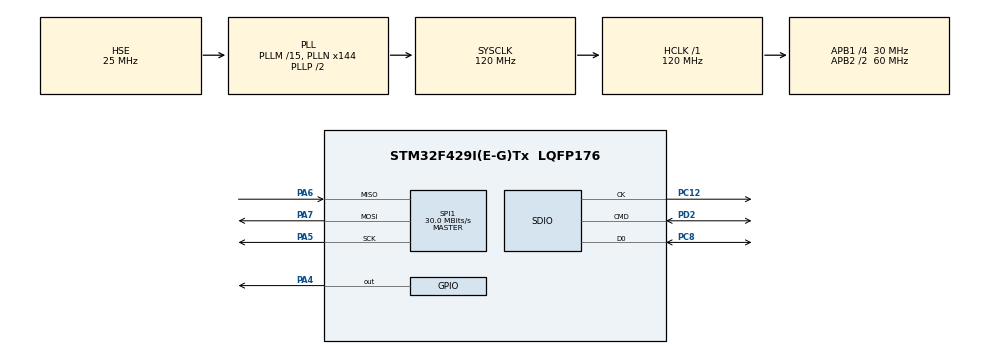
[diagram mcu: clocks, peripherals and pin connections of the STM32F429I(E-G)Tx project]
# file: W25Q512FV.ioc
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Dma.Request0=SDIO_RX
Dma.Request1=SDIO_TX
Dma.SDIO_RX.0.Direction=DMA_PERIPH_TO_MEMORY
Dma.SDIO_RX.0.FIFOMode=DMA_FIFOMODE_ENABLE
Dma.SDIO_RX.0.FIFOThreshold=DMA_FIFO_THRESHOLD_FULL
Dma.SDIO_RX.0.Instance=DMA2_Stream3
Dma.SDIO_RX.0.MemBurst=DMA_MBURST_INC4
Dma.SDIO_RX.0.MemDataAlignment=DMA_MDATAALIGN_WORD
Dma.SDIO_RX.0.MemInc=DMA_MINC_ENABLE
Dma.SDIO_RX.0.Mode=DMA_PFCTRL
Dma.SDIO_RX.0.PeriphBurst=DMA_PBURST_INC4
Dma.SDIO_RX.0.PeriphDataAlignment=DMA_PDATAALIGN_WORD
Dma.SDIO_RX.0.PeriphInc=DMA_PINC_DISABLE
Dma.SDIO_RX.0.Priority=DMA_PRIORITY_MEDIUM
Dma.SDIO_TX.1.Direction=DMA_MEMORY_TO_PERIPH
Dma.SDIO_TX.1.FIFOMode=DMA_FIFOMODE_ENABLE
Dma.SDIO_TX.1.FIFOThreshold=DMA_FIFO_THRESHOLD_FULL
Dma.SDIO_TX.1.Instance=DMA2_Stream6
Dma.SDIO_TX.1.MemBurst=DMA_MBURST_INC4
Dma.SDIO_TX.1.MemDataAlignment=DMA_MDATAALIGN_WORD
Dma.SDIO_TX.1.MemInc=DMA_MINC_ENABLE
Dma.SDIO_TX.1.Mode=DMA_PFCTRL
Dma.SDIO_TX.1.PeriphBurst=DMA_PBURST_INC4
Dma.SDIO_TX.1.PeriphDataAlignment=DMA_PDATAALIGN_WORD
Dma.SDIO_TX.1.PeriphInc=DMA_PINC_DISABLE
Dma.SDIO_TX.1.Priority=DMA_PRIORITY_LOW
Mcu.Family=STM32F4
Mcu.Name=STM32F429I(E-G)Tx
Mcu.Package=LQFP176
NVIC.DMA2_Stream3_IRQn=true\:0\:0\:false\:false\:true\:false\:true\:true
NVIC.DMA2_Stream6_IRQn=true\:0\:0\:false\:false\:true\:false\:true\:true
NVIC.PriorityGroup=NVIC_PRIORITYGROUP_4
NVIC.SDIO_IRQn=true\:0\:0\:false\:false\:true\:true\:true\:true
NVIC.TIM4_IRQn=true\:0\:0\:true\:false\:true\:false\:true\:true
NVIC.TimeBase=TIM4_IRQn
NVIC.TimeBaseIP=TIM4
PA13.Mode=Serial_Wire
PA13.Signal=SYS_JTMS-SWDIO
PA14.Mode=Serial_Wire
PA14.Signal=SYS_JTCK-SWCLK
PA4.GPIO_Speed=GPIO_SPEED_FREQ_HIGH
PA4.PinState=GPIO_PIN_SET
PA4.Signal=GPIO_Output
PA5.Mode=Full_Duplex_Master
PA5.Signal=SPI1_SCK
PA6.Mode=Full_Duplex_Master
PA6.Signal=SPI1_MISO
PA7.Mode=Full_Duplex_Master
PA7.Signal=SPI1_MOSI
PC12.Mode=SD_1_bit
PC12.Signal=SDIO_CK
PC14/OSC32_IN.Mode=LSE-External-Oscillator
PC14/OSC32_IN.Signal=RCC_OSC32_IN
PC15/OSC32_OUT.Mode=LSE-External-Oscillator
PC15/OSC32_OUT.Signal=RCC_OSC32_OUT
PC8.Mode=SD_1_bit
PC8.Signal=SDIO_D0
PD2.Mode=SD_1_bit
PD2.Signal=SDIO_CMD
PH0/OSC_IN.Mode=HSE-External-Oscillator
PH0/OSC_IN.Signal=RCC_OSC_IN
PH1/OSC_OUT.Mode=HSE-External-Oscillator
PH1/OSC_OUT.Signal=RCC_OSC_OUT
ProjectManager.HeapSize=0x200
ProjectManager.StackSize=0x400
ProjectManager.TargetToolchain=STM32CubeIDE
RCC.48MHZClocksFreq_Value=48000000
RCC.AHBFreq_Value=120000000
RCC.APB1CLKDivider=RCC_HCLK_DIV4
RCC.APB1Freq_Value=30000000
RCC.APB1TimFreq_Value=60000000
RCC.APB2CLKDivider=RCC_HCLK_DIV2
RCC.APB2Freq_Value=60000000
RCC.APB2TimFreq_Value=120000000
RCC.CortexFreq_Value=120000000
RCC.HCLKFreq_Value=120000000
RCC.HSE_VALUE=25000000
RCC.HSI_VALUE=16000000
RCC.PLLM=15
RCC.PLLN=144
RCC.PLLQ=5
RCC.PLLSourceVirtual=RCC_PLLSOURCE_HSE
RCC.SYSCLKFreq_VALUE=120000000
RCC.SYSCLKSource=RCC_SYSCLKSOURCE_PLLCLK
RCC.VCOOutputFreq_Value=240000000
SPI1.BaudRatePrescaler=SPI_BAUDRATEPRESCALER_2
SPI1.CalculateBaudRate=30.0 MBits/s
SPI1.Direction=SPI_DIRECTION_2LINES
SPI1.Mode=SPI_MODE_MASTER
SPI1.VirtualType=VM_MASTER
VP_SYS_VS_tim4.Mode=TIM4
board=custom

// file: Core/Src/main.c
/* USER CODE BEGIN Header */
/**
  ******************************************************************************
  * @file           : main.c
  * @brief          : Main program body
  ******************************************************************************
  * @attention
  *
  * Copyright (c) 2025 STMicroelectronics.
  * All rights reserved.
  *
  * This software is licensed under terms that can be found in the LICENSE file
  * in the root directory of this software component.
  * If no LICENSE file comes with this software, it is provided AS-IS.
  *
  ******************************************************************************
  */
/* USER CODE END Header */
#include "main.h"
#include "dma.h"
#include "sdio.h"
#include "spi.h"
#include "gpio.h"

/* USER CODE BEGIN Includes */
#include "w25q512.h"
#include "SD.h"
#include "Test1.h"
#include "SDToFlash.h"
/* USER CODE END Includes */

void SystemClock_Config(void);

int main(void)
{

  /* MCU Configuration--------------------------------------------------------*/

  /* Reset of all peripherals, Initializes the Flash interface and the Systick. */
  HAL_Init();

  /* Configure the system clock */
  SystemClock_Config();

  /* USER CODE BEGIN SysInit */
  app_log("right f429");
  /* USER CODE END SysInit */

  /* Initialize all configured peripherals */
  MX_GPIO_Init();
  MX_DMA_Init();
  MX_SPI1_Init();
  MX_SDIO_SD_Init();
  /* USER CODE BEGIN 2 */
  W25Q512Init();
  app_log("right f429");

//  SDToFlashTest();
  TraversalDirectory("1:");
//  TraversalDirectory("0:");
//  ReadFileCatalogue();

  /* USER CODE END 2 */

  /* Infinite loop */
  while (1)
  {

  }
}

void SystemClock_Config(void)
{
  RCC_OscInitTypeDef RCC_OscInitStruct = {0};
  RCC_ClkInitTypeDef RCC_ClkInitStruct = {0};

  /** Configure the main internal regulator output voltage
  */
  __HAL_RCC_PWR_CLK_ENABLE();
  __HAL_PWR_VOLTAGESCALING_CONFIG(PWR_REGULATOR_VOLTAGE_SCALE3);

  /** Initializes the RCC Oscillators according to the specified parameters
  * in the RCC_OscInitTypeDef structure.
  */
  RCC_OscInitStruct.OscillatorType = RCC_OSCILLATORTYPE_HSE;
  RCC_OscInitStruct.HSEState = RCC_HSE_ON;
  RCC_OscInitStruct.PLL.PLLState = RCC_PLL_ON;
  RCC_OscInitStruct.PLL.PLLSource = RCC_PLLSOURCE_HSE;
  RCC_OscInitStruct.PLL.PLLM = 15;
  RCC_OscInitStruct.PLL.PLLN = 144;
  RCC_OscInitStruct.PLL.PLLP = RCC_PLLP_DIV2;
  RCC_OscInitStruct.PLL.PLLQ = 5;
  if (HAL_RCC_OscConfig(&RCC_OscInitStruct) != HAL_OK)
  {
    Error_Handler();
  }

  /** Initializes the CPU, AHB and APB buses clocks
  */
  RCC_ClkInitStruct.ClockType = RCC_CLOCKTYPE_HCLK|RCC_CLOCKTYPE_SYSCLK
                              |RCC_CLOCKTYPE_PCLK1|RCC_CLOCKTYPE_PCLK2;
  RCC_ClkInitStruct.SYSCLKSource = RCC_SYSCLKSOURCE_PLLCLK;
  RCC_ClkInitStruct.AHBCLKDivider = RCC_SYSCLK_DIV1;
  RCC_ClkInitStruct.APB1CLKDivider = RCC_HCLK_DIV4;
  RCC_ClkInitStruct.APB2CLKDivider = RCC_HCLK_DIV2;

  if (HAL_RCC_ClockConfig(&RCC_ClkInitStruct, FLASH_LATENCY_3) != HAL_OK)
  {
    Error_Handler();
  }
}

void HAL_TIM_PeriodElapsedCallback(TIM_HandleTypeDef *htim)
{
  if (htim->Instance == TIM4) {
    HAL_IncTick();
  }
}

void Error_Handler(void)
{
  __disable_irq();
  while (1)
  {
  }
}
